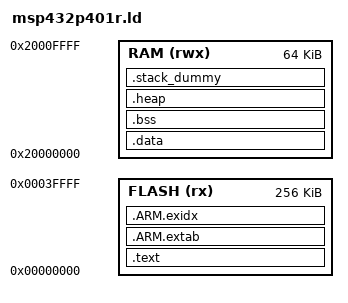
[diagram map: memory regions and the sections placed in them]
/******************************************************
 * GCC linker script for Texas Instruments MSP432P401R
 ******************************************************/

/* Device specific values */

#define ROM_START   0x00000000
#define ROM_SIZE    0x00040000
#define RAM_START   0x20000000
#define RAM_SIZE    0x00010000
#define INFO_START  0x00200000
#define INFO_SIZE   0x00004000

/* Common - Do not change */

#if !defined(MBED_APP_START)
  #define MBED_APP_START ROM_START
#endif

#if !defined(MBED_APP_SIZE)
  #define MBED_APP_SIZE ROM_SIZE
#endif

#if !defined(MBED_BOOT_STACK_SIZE)
    #define  MBED_BOOT_STACK_SIZE 0x400
#endif

STACK_SIZE = MBED_BOOT_STACK_SIZE;

/* Linker script to configure memory regions. */
/* 0x1AC resevered for vectors; 8-byte aligned = 0x1B0 (0x1AC + 0x4)*/
MEMORY
{
    FLASH (rx)   : ORIGIN = MBED_APP_START, LENGTH = MBED_APP_SIZE
    RAM   (rwx)  : ORIGIN = RAM_START,      LENGTH = RAM_SIZE
}

/* Linker script to place sections and symbol values. Should be used together
 * with other linker script that defines memory regions FLASH and RAM.
 * It references following symbols, which must be defined in code:
 *   Reset_Handler : Entry of reset handler
 *
 * It defines following symbols, which code can use without definition:
 *   __exidx_start
 *   __exidx_end
 *   __etext
 *   __data_start__
 *   __preinit_array_start
 *   __preinit_array_end
 *   __init_array_start
 *   __init_array_end
 *   __fini_array_start
 *   __fini_array_end
 *   __data_end__
 *   __bss_start__
 *   __bss_end__
 *   __end__
 *   end
 *   __HeapLimit
 *   __StackLimit
 *   __StackTop
 *   __stack
 */

ENTRY(Reset_Handler)

SECTIONS
{
    .text :
    {
        KEEP(*(.isr_vector))
        *(.text*)

        KEEP(*(.init))
        KEEP(*(.fini))

        /* .ctors */
        *crtbegin.o(.ctors)
        *crtbegin?.o(.ctors)
        *(EXCLUDE_FILE(*crtend?.o *crtend.o) .ctors)
        *(SORT(.ctors.*))
        *(.ctors)

        /* .dtors */
        *crtbegin.o(.dtors)
        *crtbegin?.o(.dtors)
        *(EXCLUDE_FILE(*crtend?.o *crtend.o) .dtors)
        *(SORT(.dtors.*))
        *(.dtors)

        *(.rodata*)

        KEEP(*(.eh_frame*))
    } > FLASH

    .ARM.extab :
    {
        *(.ARM.extab* .gnu.linkonce.armextab.*)
    } > FLASH

    __exidx_start = .;
    .ARM.exidx :
    {
        *(.ARM.exidx* .gnu.linkonce.armexidx.*)
    } > FLASH
    __exidx_end = .;

    /* Location counter can end up 2byte aligned with narrow Thumb code but
       __etext is assumed by startup code to be the LMA of a section in RAM
       which must be 4byte aligned */
    __etext = ALIGN (4);
    __data_load__ = .;

    .data : AT (__etext)
    {
        __data_start__ = .;
        *(vtable)
        *(.data*)

        . = ALIGN(4);
        /* preinit data */
        PROVIDE_HIDDEN (__preinit_array_start = .);
        KEEP(*(.preinit_array))
        PROVIDE_HIDDEN (__preinit_array_end = .);

        . = ALIGN(4);
        /* init data */
        PROVIDE_HIDDEN (__init_array_start = .);
        KEEP(*(SORT(.init_array.*)))
        KEEP(*(.init_array))
        PROVIDE_HIDDEN (__init_array_end = .);

        . = ALIGN(4);
        /* finit data */
        PROVIDE_HIDDEN (__fini_array_start = .);
        KEEP(*(SORT(.fini_array.*)))
        KEEP(*(.fini_array))
        PROVIDE_HIDDEN (__fini_array_end = .);

        KEEP(*(.jcr*))
        . = ALIGN(4);
        /* All data end */
        __data_end__ = .;

    } > RAM

    .bss :
    {
        . = ALIGN(4);
        __bss_start__ = .;
        *(.bss*)
        *(COMMON)
        . = ALIGN(4);
        __bss_end__ = .;
    } > RAM

    .heap (COPY):
    {
        __end__ = .;
        PROVIDE(end = .);
        *(.heap*)
        . = ORIGIN(RAM) + LENGTH(RAM) - STACK_SIZE;
        __HeapLimit = .;
    } > RAM

    /* .stack_dummy section doesn't contains any symbols. It is only
     * used for linker to calculate size of stack sections, and assign
     * values to stack symbols later */
    .stack_dummy (COPY):
    {
        *(.stack*)
    } > RAM

    /* Set stack top to end of RAM, and stack limit move down by
     * size of stack_dummy section */
    __StackTop   = ORIGIN(RAM) + LENGTH(RAM);
    __StackLimit = __StackTop - STACK_SIZE;
    PROVIDE(__stack = __StackTop);

    /* Check if data + heap + stack exceeds RAM limit */
    ASSERT(__StackLimit >= __HeapLimit, "region RAM overflowed with stack")
}
